# BL808 register map
Vendor: Bouffalo Lab; File version: 0.1
Bouffalo BL808 chip
Registers are 32-bit, read-write, reset 0x0 unless marked. A register's access mark holds for its fields unless they carry their own. Offsets are from the block's base; lines under a group give offsets from that group; [hi:lo] are bit positions; {n}, {i} and the like mark numbered series; 'fields as' and 'values as' point back to an identical list; <NAME> marks a mode.

## Memory map
0x20000000 GLB size 0x1000 — Global configuration register
0x20002000 GPIP size 0x400 — Generic DAC, ADC and ACOMP interface control
0x20005000 TZC_SEC size 0x1000 — Trust zone isolation
0x20006000 TZC_NSEC size 0x1000 — Trust zone isolation 2
0x20008000 CCI size 0x1000 — Camera Control Interface
0x20009000 MISC size 0x1000 — Chip Miscellaneous control
0x2000A800 IPC size 0x100 — Inter-processor Channel
0x2000B000 FLASH size 0x400 — Quad Serial Flash control
0x2000E000 PDS_BASE size 0xB00 — Sleep control (Power-down sleep?)
0x2000F000 HBN size 0x800 — Hibernate (Deep sleep) control
0x2000F800 AON size 0x1000 — Always-On function control
0x20052000 PSRAM size 0x200 — Pseudo Static Random Access Memory control
0x20056000 EF_DATA size 0x1000
0x20060000 SDH size 0x1000 — Secure Digital host control
0x30020000 CODEC size 0x1000 — Codec miscellaneous control

## CODEC — Codec miscellaneous control
Base 0x30020000
0x00 codec_bus_ctrl reset 0xFFFF
  [15:0] rg_pclk_force_on
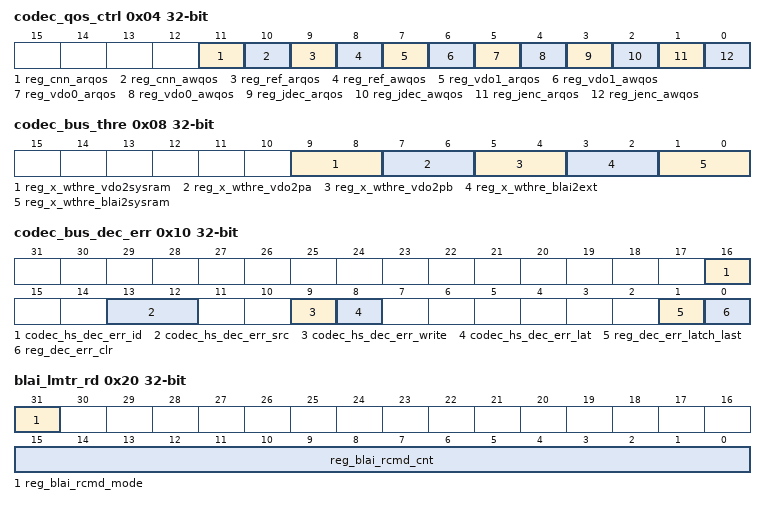
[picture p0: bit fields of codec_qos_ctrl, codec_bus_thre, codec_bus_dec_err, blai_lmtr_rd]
0x04 codec_qos_ctrl
  [11] reg_cnn_arqos, [10] reg_cnn_awqos, [9] reg_ref_arqos, [8] reg_ref_awqos, [7] reg_vdo1_arqos, [6] reg_vdo1_awqos, [5] reg_vdo0_arqos, [4] reg_vdo0_awqos, [3] reg_jdec_arqos, [2] reg_jdec_awqos, [1] reg_jenc_arqos, [0] reg_jenc_awqos
0x08 codec_bus_thre
  [9:8] reg_x_wthre_vdo2sysram, [7:6] reg_x_wthre_vdo2pa, [5:4] reg_x_wthre_vdo2pb, [3:2] reg_x_wthre_blai2ext, [1:0] reg_x_wthre_blai2sysram
0x10 codec_bus_dec_err
  [16] codec_hs_dec_err_id ro, [13:12] codec_hs_dec_err_src ro, [9] codec_hs_dec_err_write ro, [8] codec_hs_dec_err_lat ro, [1] reg_dec_err_latch_last, [0] reg_dec_err_clr
0x14 codec_bus_dec_err_addr
  [31:0] codec_hs_dec_err_addr ro
0x20 blai_lmtr_rd
  [31] reg_blai_rcmd_mode, [15:0] reg_blai_rcmd_cnt
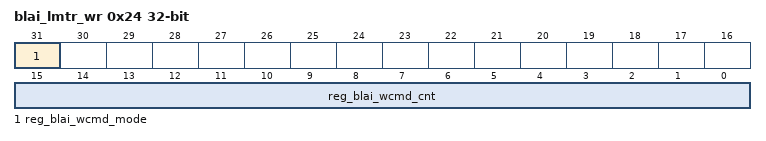
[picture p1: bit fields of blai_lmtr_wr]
0x24 blai_lmtr_wr
  [31] reg_blai_wcmd_mode, [15:0] reg_blai_wcmd_cnt
0x28 id_selection
  [0] rg_jenc_id_sel
0xFC codec_misc_dummy reset 0xFFFF0000
  [31:0] dummy_reg

## GPIP — Generic DAC, ADC and ACOMP interface control
Base 0x20002000
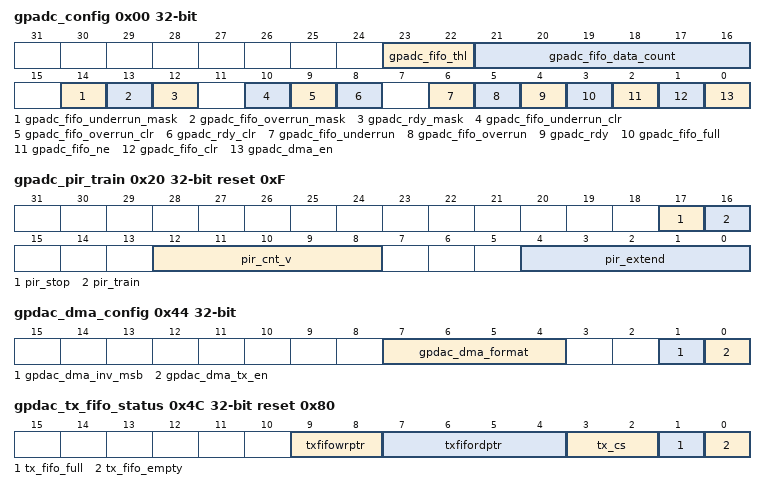
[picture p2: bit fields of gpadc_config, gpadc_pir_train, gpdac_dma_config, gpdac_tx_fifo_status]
0x00 gpadc_config
  [23:22] gpadc_fifo_thl, [21:16] gpadc_fifo_data_count ro, [14] gpadc_fifo_underrun_mask, [13] gpadc_fifo_overrun_mask, [12] gpadc_rdy_mask, [10] gpadc_fifo_underrun_clr, [9] gpadc_fifo_overrun_clr, [8] gpadc_rdy_clr, [6] gpadc_fifo_underrun ro, [5] gpadc_fifo_overrun ro, [4] gpadc_rdy ro, [3] gpadc_fifo_full ro, [2] gpadc_fifo_ne ro, [1] gpadc_fifo_clr wo, [0] gpadc_dma_en
0x04 gpadc_dma_rdata
  [25:0] gpadc_dma_rdata ro
0x20 gpadc_pir_train reset 0xF
  [17] pir_stop ro, [16] pir_train, [12:8] pir_cnt_v ro, [4:0] pir_extend
0x40 gpdac_config
  [0] gpdac_en
0x44 gpdac_dma_config
  [7:4] gpdac_dma_format, [1] gpdac_dma_inv_msb, [0] gpdac_dma_tx_en
0x48 gpdac_dma_wdata
0x4C gpdac_tx_fifo_status reset 0x80
  [9:8] txfifowrptr ro, [7:4] txfifordptr ro, [3:2] tx_cs ro, [1] tx_fifo_full ro, [0] tx_fifo_empty ro

## HBN — Hibernate (Deep sleep) control
Base 0x2000F000
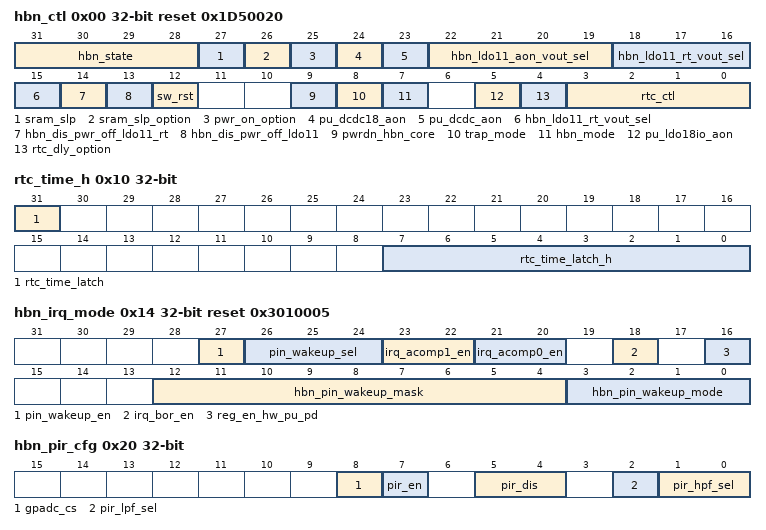
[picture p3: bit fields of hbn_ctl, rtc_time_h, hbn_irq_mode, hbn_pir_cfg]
0x00 hbn_ctl reset 0x1D50020
  [31:28] hbn_state ro, [27] sram_slp ro, [26] sram_slp_option, [25] pwr_on_option, [24] pu_dcdc18_aon, [23] pu_dcdc_aon, [22:19] hbn_ldo11_aon_vout_sel, [18:15] hbn_ldo11_rt_vout_sel, [14] hbn_dis_pwr_off_ldo11_rt, [13] hbn_dis_pwr_off_ldo11, [12] sw_rst, [9] pwrdn_hbn_core, [8] trap_mode ro, [7] hbn_mode wo, [5] pu_ldo18io_aon, [4] rtc_dly_option, [3:0] rtc_ctl
0x04 hbn_time_l
0x08 hbn_time_h
  [7:0] hbn_time_h
0x0C rtc_time_l
  [31:0] rtc_time_latch_l ro
0x10 rtc_time_h
  [31] rtc_time_latch wo, [7:0] rtc_time_latch_h ro
0x14 hbn_irq_mode reset 0x3010005
  [27] pin_wakeup_en, [26:24] pin_wakeup_sel, [23:22] irq_acomp1_en, [21:20] irq_acomp0_en, [18] irq_bor_en, [16] reg_en_hw_pu_pd, [12:4] hbn_pin_wakeup_mask, [3:0] hbn_pin_wakeup_mode
0x18 hbn_irq_stat
  [31:0] irq_stat ro
0x1C hbn_irq_clr
  [31:0] irq_clr wo
0x20 hbn_pir_cfg
  [8] gpadc_cs, [7] pir_en, [5:4] pir_dis, [2] pir_lpf_sel, [1:0] pir_hpf_sel
0x24 hbn_pir_vth reset 0x3FF
  [13:0] pir_vth
0x28 hbn_pir_interval reset 0xA3D
  [11:0] pir_interval
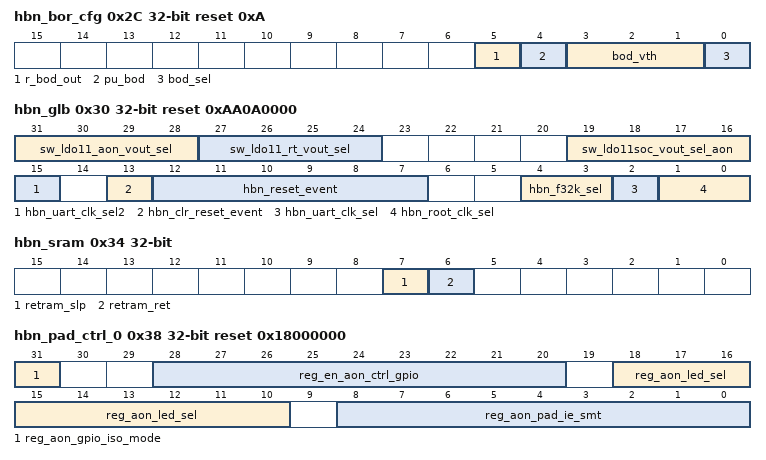
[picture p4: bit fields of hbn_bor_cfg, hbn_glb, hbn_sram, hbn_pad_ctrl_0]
0x2C hbn_bor_cfg reset 0xA
  [5] r_bod_out ro, [4] pu_bod, [3:1] bod_vth, [0] bod_sel
0x30 hbn_glb reset 0xAA0A0000
  [31:28] sw_ldo11_aon_vout_sel, [27:24] sw_ldo11_rt_vout_sel, [19:16] sw_ldo11soc_vout_sel_aon, [15] hbn_uart_clk_sel2, [13] hbn_clr_reset_event, [12:7] hbn_reset_event ro, [4:3] hbn_f32k_sel, [2] hbn_uart_clk_sel, [1:0] hbn_root_clk_sel
0x34 hbn_sram
  [7] retram_slp, [6] retram_ret
0x38 hbn_pad_ctrl_0 reset 0x18000000
  [31] reg_aon_gpio_iso_mode, [28:20] reg_en_aon_ctrl_gpio, [18:10] reg_aon_led_sel, [8:0] reg_aon_pad_ie_smt
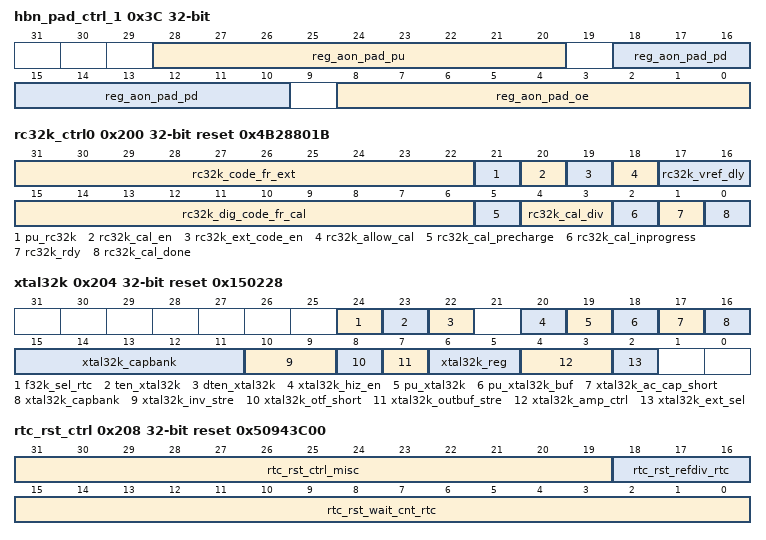
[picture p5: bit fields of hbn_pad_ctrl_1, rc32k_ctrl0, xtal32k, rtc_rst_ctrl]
0x3C hbn_pad_ctrl_1
  [28:20] reg_aon_pad_pu, [18:10] reg_aon_pad_pd, [8:0] reg_aon_pad_oe
0x100 hbn_rsv0
0x104 hbn_rsv1 reset 0xFFFFFFFF
0x108 hbn_rsv2
0x10C hbn_rsv3 reset 0xFFFFFFFF
0x200 rc32k_ctrl0 reset 0x4B28801B
  [31:22] rc32k_code_fr_ext, [21] pu_rc32k, [20] rc32k_cal_en, [19] rc32k_ext_code_en, [18] rc32k_allow_cal, [17:16] rc32k_vref_dly, [15:6] rc32k_dig_code_fr_cal ro, [5] rc32k_cal_precharge ro, [4:3] rc32k_cal_div, [2] rc32k_cal_inprogress ro, [1] rc32k_rdy ro, [0] rc32k_cal_done ro
0x204 xtal32k reset 0x150228
  [24] f32k_sel_rtc, [23] ten_xtal32k, [22] dten_xtal32k, [20] xtal32k_hiz_en, [19] pu_xtal32k, [18] pu_xtal32k_buf, [17] xtal32k_ac_cap_short, [16:11] xtal32k_capbank, [10:9] xtal32k_inv_stre, [8] xtal32k_otf_short, [7] xtal32k_outbuf_stre, [6:5] xtal32k_reg, [4:3] xtal32k_amp_ctrl, [2] xtal32k_ext_sel
0x208 rtc_rst_ctrl reset 0x50943C00
  [31:19] rtc_rst_ctrl_misc, [18:16] rtc_rst_refdiv_rtc, [15:0] rtc_rst_wait_cnt_rtc
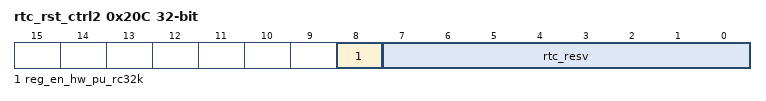
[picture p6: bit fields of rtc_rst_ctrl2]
0x20C rtc_rst_ctrl2
  [8] reg_en_hw_pu_rc32k, [7:0] rtc_resv

## Licence text in the file
Copyright (c) 2022 Bouffalo Lab bl808-pac is licensed under Mulan PSL v2. You can use this software according to the terms and conditions of the Mulan PSL v2. You may obtain a copy of Mulan PSL v2 at: http://license.coscl.org.cn/MulanPSL2 THIS SOFTWARE IS PROVIDED ON AN "AS IS" BASIS, WITHOUT WARRANTIES OF ANY KIND, EITHER EXPRESS OR IMPLIED, INCLUDING BUT NOT LIMITED TO NON-INFRINGEMENT, MERCHANTABILITY OR FIT FOR A PARTICULAR PURPOSE. See the Mulan PSL v2 for more details.
